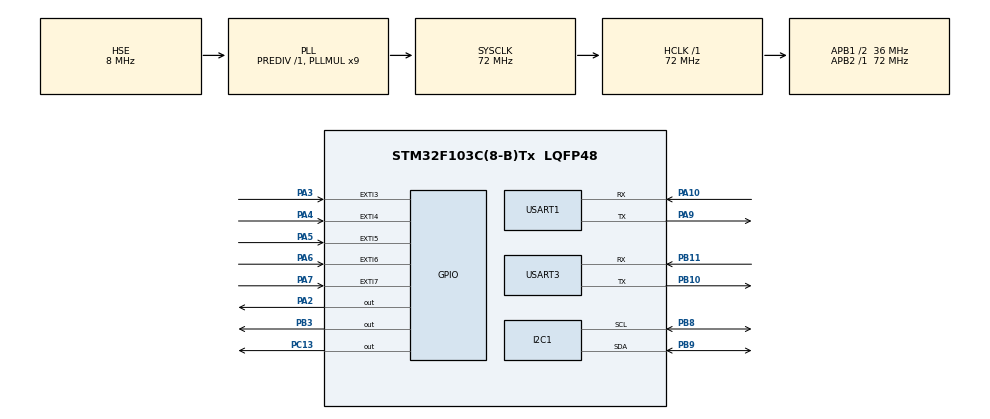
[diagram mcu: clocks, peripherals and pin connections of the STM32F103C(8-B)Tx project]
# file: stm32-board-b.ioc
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Mcu.Family=STM32F1
Mcu.Name=STM32F103C(8-B)Tx
Mcu.Package=LQFP48
NVIC.EXTI3_IRQn=true\:0\:0\:false\:false\:true\:true\:true\:true
NVIC.EXTI4_IRQn=true\:0\:0\:false\:false\:true\:true\:true\:true
NVIC.EXTI9_5_IRQn=true\:0\:0\:false\:false\:true\:true\:true\:true
NVIC.PriorityGroup=NVIC_PRIORITYGROUP_4
NVIC.TIM2_IRQn=true\:0\:0\:false\:false\:true\:true\:true\:true
NVIC.TIM3_IRQn=true\:0\:0\:false\:false\:true\:true\:true\:true
NVIC.TIM4_IRQn=true\:0\:0\:false\:false\:true\:true\:true\:true
NVIC.USART1_IRQn=true\:0\:0\:false\:false\:true\:true\:true\:true
NVIC.USART3_IRQn=true\:0\:0\:false\:false\:true\:true\:true\:true
PA10.Mode=Asynchronous
PA10.Signal=USART1_RX
PA13.Mode=Serial_Wire
PA13.Signal=SYS_JTMS-SWDIO
PA14.Mode=Serial_Wire
PA14.Signal=SYS_JTCK-SWCLK
PA2.Signal=GPIO_Output
PA3.GPIO_ModeDefaultEXTI=GPIO_MODE_IT_FALLING
PA3.GPIO_PuPd=GPIO_PULLUP
PA3.Signal=GPXTI3
PA4.GPIO_ModeDefaultEXTI=GPIO_MODE_IT_FALLING
PA4.GPIO_PuPd=GPIO_PULLUP
PA4.Signal=GPXTI4
PA5.GPIO_ModeDefaultEXTI=GPIO_MODE_IT_FALLING
PA5.GPIO_PuPd=GPIO_PULLUP
PA5.Signal=GPXTI5
PA6.GPIO_ModeDefaultEXTI=GPIO_MODE_IT_FALLING
PA6.GPIO_PuPd=GPIO_PULLUP
PA6.Signal=GPXTI6
PA7.GPIO_ModeDefaultEXTI=GPIO_MODE_IT_FALLING
PA7.GPIO_PuPd=GPIO_PULLUP
PA7.Signal=GPXTI7
PA9.Mode=Asynchronous
PA9.Signal=USART1_TX
PB10.Mode=Asynchronous
PB10.Signal=USART3_TX
PB11.Mode=Asynchronous
PB11.Signal=USART3_RX
PB3.PinState=GPIO_PIN_SET
PB3.Signal=GPIO_Output
PB8.Mode=I2C
PB8.Signal=I2C1_SCL
PB9.Mode=I2C
PB9.Signal=I2C1_SDA
PC13-TAMPER-RTC.Signal=GPIO_Output
PC14-OSC32_IN.Mode=LSE-External-Oscillator
PC14-OSC32_IN.Signal=RCC_OSC32_IN
PC15-OSC32_OUT.Mode=LSE-External-Oscillator
PC15-OSC32_OUT.Signal=RCC_OSC32_OUT
PD0-OSC_IN.Mode=HSE-External-Oscillator
PD0-OSC_IN.Signal=RCC_OSC_IN
PD1-OSC_OUT.Mode=HSE-External-Oscillator
PD1-OSC_OUT.Signal=RCC_OSC_OUT
ProjectManager.HeapSize=0x200
ProjectManager.StackSize=0x400
ProjectManager.TargetToolchain=MDK-ARM V5.32
RCC.ADCPresc=RCC_ADCPCLK2_DIV6
RCC.AHBFreq_Value=72000000
RCC.APB1CLKDivider=RCC_HCLK_DIV2
RCC.APB1Freq_Value=36000000
RCC.APB1TimFreq_Value=72000000
RCC.APB2Freq_Value=72000000
RCC.APB2TimFreq_Value=72000000
RCC.HCLKFreq_Value=72000000
RCC.PLLMUL=RCC_PLL_MUL9
RCC.PLLSourceVirtual=RCC_PLLSOURCE_HSE
RCC.SYSCLKFreq_VALUE=72000000
RCC.SYSCLKSource=RCC_SYSCLKSOURCE_PLLCLK
RCC.USBFreq_Value=72000000
TIM2.Period=999
TIM2.Prescaler=7199
TIM3.AutoReloadPreload=TIM_AUTORELOAD_PRELOAD_ENABLE
TIM3.Period=8999
TIM3.Prescaler=719
TIM4.Period=999
TIM4.Prescaler=7199
USART1.VirtualMode=VM_ASYNC
USART3.VirtualMode=VM_ASYNC
VP_RTC_VS_RTC_Activate.Mode=RTC_Enabled
VP_RTC_VS_RTC_Calendar.Mode=RTC_Calendar
VP_TIM2_VS_ClockSourceINT.Mode=Internal
VP_TIM3_VS_ClockSourceINT.Mode=Internal
VP_TIM4_VS_ClockSourceINT.Mode=Internal
board=custom

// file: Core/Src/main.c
/* USER CODE BEGIN Header */
/**
 ******************************************************************************
 * @file           : main.c
 * @brief          : Main program body
 ******************************************************************************
 * @attention
 *
 * Copyright (c) 2025 STMicroelectronics.
 * All rights reserved.
 *
 * This software is licensed under terms that can be found in the LICENSE file
 * in the root directory of this software component.
 * If no LICENSE file comes with this software, it is provided AS-IS.
 *
 ******************************************************************************
 */
/* USER CODE END Header */
#include "main.h"
#include "i2c.h"
#include "rtc.h"
#include "tim.h"
#include "usart.h"
#include "gpio.h"

/* USER CODE BEGIN Includes */
#include "user.h"
/* USER CODE END Includes */

void SystemClock_Config(void);

int main(void)
{

  /* MCU Configuration--------------------------------------------------------*/

  /* Reset of all peripherals, Initializes the Flash interface and the Systick. */
  HAL_Init();

  /* Configure the system clock */
  SystemClock_Config();

  /* Initialize all configured peripherals */
  MX_GPIO_Init();
  MX_I2C1_Init();
  MX_TIM2_Init();
  MX_TIM3_Init();
  MX_TIM4_Init();
  MX_USART1_UART_Init();
  MX_USART3_UART_Init();
  MX_RTC_Init();
  /* USER CODE BEGIN 2 */
  setup(); // 调用用户定义的 setup 函数
  /* USER CODE END 2 */

  /* Infinite loop */
  /* USER CODE BEGIN WHILE */
  while (1)
  {
    loop(); // 调用用户定义的 loop 函数
    /* USER CODE END WHILE */

  }
}

void SystemClock_Config(void)
{
  RCC_OscInitTypeDef RCC_OscInitStruct = {0};
  RCC_ClkInitTypeDef RCC_ClkInitStruct = {0};
  RCC_PeriphCLKInitTypeDef PeriphClkInit = {0};

  /** Initializes the RCC Oscillators according to the specified parameters
  * in the RCC_OscInitTypeDef structure.
  */
  RCC_OscInitStruct.OscillatorType = RCC_OSCILLATORTYPE_LSI|RCC_OSCILLATORTYPE_HSE;
  RCC_OscInitStruct.HSEState = RCC_HSE_ON;
  RCC_OscInitStruct.HSEPredivValue = RCC_HSE_PREDIV_DIV1;
  RCC_OscInitStruct.HSIState = RCC_HSI_ON;
  RCC_OscInitStruct.LSIState = RCC_LSI_ON;
  RCC_OscInitStruct.PLL.PLLState = RCC_PLL_ON;
  RCC_OscInitStruct.PLL.PLLSource = RCC_PLLSOURCE_HSE;
  RCC_OscInitStruct.PLL.PLLMUL = RCC_PLL_MUL9;
  if (HAL_RCC_OscConfig(&RCC_OscInitStruct) != HAL_OK)
  {
    Error_Handler();
  }

  /** Initializes the CPU, AHB and APB buses clocks
  */
  RCC_ClkInitStruct.ClockType = RCC_CLOCKTYPE_HCLK|RCC_CLOCKTYPE_SYSCLK
                              |RCC_CLOCKTYPE_PCLK1|RCC_CLOCKTYPE_PCLK2;
  RCC_ClkInitStruct.SYSCLKSource = RCC_SYSCLKSOURCE_PLLCLK;
  RCC_ClkInitStruct.AHBCLKDivider = RCC_SYSCLK_DIV1;
  RCC_ClkInitStruct.APB1CLKDivider = RCC_HCLK_DIV2;
  RCC_ClkInitStruct.APB2CLKDivider = RCC_HCLK_DIV1;

  if (HAL_RCC_ClockConfig(&RCC_ClkInitStruct, FLASH_LATENCY_2) != HAL_OK)
  {
    Error_Handler();
  }
  PeriphClkInit.PeriphClockSelection = RCC_PERIPHCLK_RTC;
  PeriphClkInit.RTCClockSelection = RCC_RTCCLKSOURCE_LSI;
  if (HAL_RCCEx_PeriphCLKConfig(&PeriphClkInit) != HAL_OK)
  {
    Error_Handler();
  }
}

void Error_Handler(void)
{
  __disable_irq();
  while (1)
  {
  }
}
